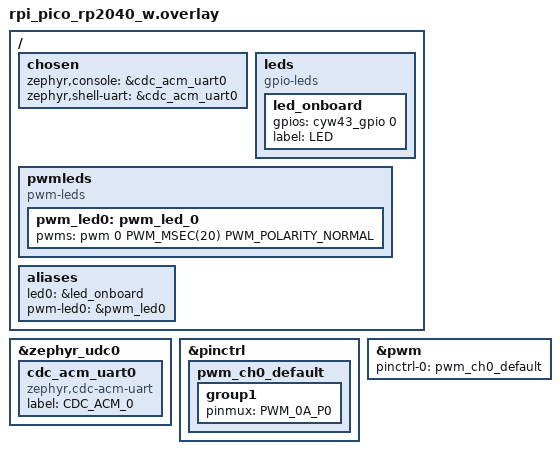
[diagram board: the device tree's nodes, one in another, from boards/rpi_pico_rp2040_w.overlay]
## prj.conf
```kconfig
CONFIG_GPIO=y
CONFIG_PWM=y
CONFIG_LOG=y

# Needed for RPI Pico W
CONFIG_CYW43439=y
CONFIG_NETWORKING=y
CONFIG_WIFI=y
CONFIG_WIFI_AIROC=y
CONFIG_GPIO_CYW43=y
CONFIG_ENTROPY_GENERATOR=y
CONFIG_TEST_RANDOM_GENERATOR=y

# USB Console configuration
CONFIG_USB_DEVICE_STACK=y
CONFIG_USB_CDC_ACM=y
CONFIG_UART_LINE_CTRL=y

CONFIG_SERIAL=y
CONFIG_CONSOLE=y
CONFIG_UART_CONSOLE=y

# Here set to redirect stdout/log to USB CDC
CONFIG_USB_DEVICE_INITIALIZE_AT_BOOT=y
```

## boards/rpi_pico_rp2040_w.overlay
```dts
// USB Console
&zephyr_udc0 {
	cdc_acm_uart0: cdc_acm_uart0 {
		compatible = "zephyr,cdc-acm-uart";
		label = "CDC_ACM_0";
	};
};

&pinctrl {
    pwm_ch0_default: pwm_ch0_default {
        group1 {
			// zephyr/include/zephyr/dt-bindings/pinctrl/rpi-pico-pinctrl-common.h
            pinmux = <PWM_0A_P0>; // PIN GPIO16, slice 0, Channel A
        };
    };
};

&pwm {
    status = "okay";
    pinctrl-0 = <&pwm_ch0_default>;
    pinctrl-names = "default";
};

/ {
	chosen {
        zephyr,console = &cdc_acm_uart0;
        zephyr,shell-uart = &cdc_acm_uart0;
    };

	leds {
		compatible = "gpio-leds";

		led_onboard: led_onboard {
			gpios = <&cyw43_gpio 0 GPIO_ACTIVE_HIGH>;
			label = "LED";
		};
	};

	pwmleds {
        compatible = "pwm-leds";
        pwm_led0: pwm_led_0 {
            pwms = <&pwm 0 PWM_MSEC(20) PWM_POLARITY_NORMAL>;
        };
    };

	aliases {
		led0 = &led_onboard;
		pwm-led0 = &pwm_led0;
	};
};
```

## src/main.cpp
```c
#include <zephyr/drivers/gpio.h>
#include <zephyr/drivers/pwm.h>
#include <zephyr/kernel.h>
#include <zephyr/logging/log.h>

#define SLEEP_TIME_MS 100

/* The devicetree node identifier for the "led0" alias. */
#define LED_NODE DT_ALIAS(led0)

static const struct gpio_dt_spec led = GPIO_DT_SPEC_GET(LED_NODE, gpios);
static const struct pwm_dt_spec pwm = PWM_DT_SPEC_GET(DT_ALIAS(pwm_led0));

LOG_MODULE_REGISTER(main, LOG_LEVEL_INF);

int main(void)
{
    uint8_t duty = 0;

    if (!gpio_is_ready_dt(&led)) return 0;
    if (!pwm_is_ready_dt(&pwm)) return 0;
    if (gpio_pin_configure_dt(&led, GPIO_OUTPUT_ACTIVE) < 0) return 0;

    int ret = 0;
    while (ret == 0) {
        if (duty % 10 == 0) {
            int gpio_ret = gpio_pin_toggle_dt(&led);
            if (gpio_ret < 0) {
                ret = gpio_ret;
            }
        }

        uint32_t period = (uint32_t)(((uint64_t)pwm.period * duty) / 255);
        ret = pwm_set_pulse_dt(&pwm, period);

        LOG_INF("PWM: %d", duty);
        k_msleep(SLEEP_TIME_MS);
        duty++;
    }

    return ret;
}
```
